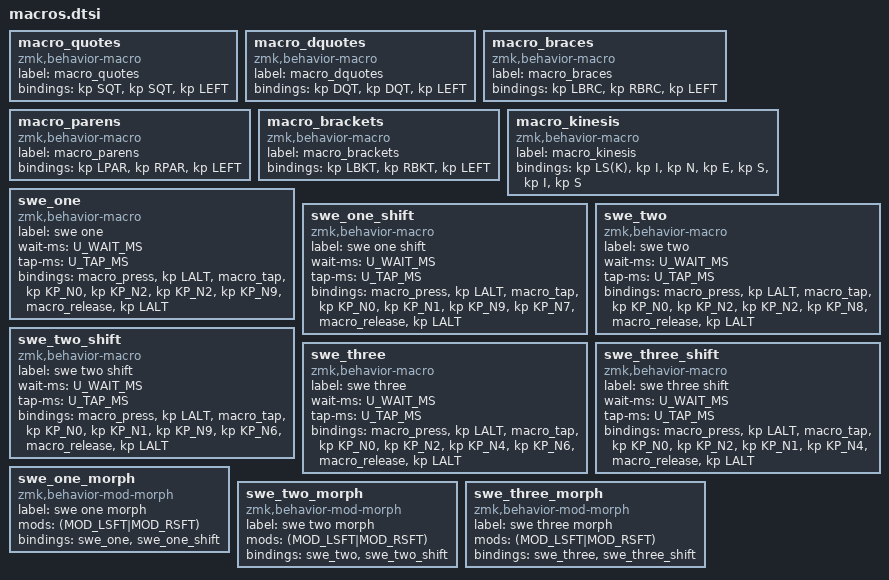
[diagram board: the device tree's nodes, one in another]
  macro_quotes: macro_quotes {
    compatible = "zmk,behavior-macro";
    label = "macro_quotes";
    #binding-cells = <0>;
    bindings = <&kp SQT>, <&kp SQT>, <&kp LEFT>;
  };
  macro_dquotes: macro_dquotes {
    compatible = "zmk,behavior-macro";
    label = "macro_dquotes";
    #binding-cells = <0>;
    bindings = <&kp DQT>, <&kp DQT>, <&kp LEFT>;
  };
  macro_braces: macro_braces {
    compatible = "zmk,behavior-macro";
    label = "macro_braces";
    #binding-cells = <0>;
    bindings = <&kp LBRC>, <&kp RBRC>, <&kp LEFT>;
  };
  macro_parens: macro_parens {
    compatible = "zmk,behavior-macro";
    label = "macro_parens";
    #binding-cells = <0>;
    bindings = <&kp LPAR>, <&kp RPAR>, <&kp LEFT>;
  };
  macro_brackets: macro_brackets {
    compatible = "zmk,behavior-macro";
    label = "macro_brackets";
    #binding-cells = <0>;
    bindings = <&kp LBKT>, <&kp RBKT>, <&kp LEFT>;
  };
  macro_kinesis: macro_kinesis {
    compatible = "zmk,behavior-macro";
    label = "macro_kinesis";
    #binding-cells = <0>;
    bindings = <&kp LS(K)>, <&kp I>, <&kp N>, <&kp E>, <&kp S>, <&kp I>, <&kp S>;
  };

  swe_one: swe_one {
      compatible = "zmk,behavior-macro";
      label = "swe one";
      #binding-cells = <0>;
      wait-ms = <U_WAIT_MS>;
      tap-ms = <U_TAP_MS>;
      bindings
        = <&macro_press   &kp LALT>
        , <&macro_tap     &kp KP_N0 &kp KP_N2 &kp KP_N2 &kp KP_N9>
        , <&macro_release &kp LALT>;
  };
  swe_one_shift: swe_one_shift {
      compatible = "zmk,behavior-macro";
      label = "swe one shift";
      #binding-cells = <0>;
      wait-ms = <U_WAIT_MS>;
      tap-ms = <U_TAP_MS>;
      bindings
        = <&macro_press   &kp LALT>
        , <&macro_tap     &kp KP_N0 &kp KP_N1 &kp KP_N9 &kp KP_N7>
        , <&macro_release &kp LALT>;
  };
  swe_two: swe_two {
      compatible = "zmk,behavior-macro";
      label = "swe two";
      #binding-cells = <0>;
      wait-ms = <U_WAIT_MS>;
      tap-ms = <U_TAP_MS>;
      bindings
        = <&macro_press   &kp LALT>
        , <&macro_tap     &kp KP_N0 &kp KP_N2 &kp KP_N2 &kp KP_N8>
        , <&macro_release &kp LALT>;
  };
  swe_two_shift: swe_two_shift {
      compatible = "zmk,behavior-macro";
      label = "swe two shift";
      #binding-cells = <0>;
      wait-ms = <U_WAIT_MS>;
      tap-ms = <U_TAP_MS>;
      bindings
        = <&macro_press   &kp LALT>
        , <&macro_tap     &kp KP_N0 &kp KP_N1 &kp KP_N9 &kp KP_N6>
        , <&macro_release &kp LALT>;
  };
  swe_three: swe_three {
      compatible = "zmk,behavior-macro";
      label = "swe three";
      #binding-cells = <0>;
      wait-ms = <U_WAIT_MS>;
      tap-ms = <U_TAP_MS>;
      bindings
        = <&macro_press   &kp LALT>
        , <&macro_tap     &kp KP_N0 &kp KP_N2 &kp KP_N4 &kp KP_N6>
        , <&macro_release &kp LALT>;
  };
  swe_three_shift: swe_three_shift {
      compatible = "zmk,behavior-macro";
      label = "swe three shift";
      #binding-cells = <0>;
      wait-ms = <U_WAIT_MS>;
      tap-ms = <U_TAP_MS>;
      bindings
        = <&macro_press   &kp LALT>
        , <&macro_tap     &kp KP_N0 &kp KP_N2 &kp KP_N1 &kp KP_N4>
        , <&macro_release &kp LALT>;
  };
  swe_one_morph: swe_one_morph {
      compatible = "zmk,behavior-mod-morph";
      label = "swe one morph";
      #binding-cells = <0>;
      mods = <(MOD_LSFT|MOD_RSFT)>;
      bindings = <&swe_one>, <&swe_one_shift>;
  };
  swe_two_morph: swe_two_morph {
      compatible = "zmk,behavior-mod-morph";
      label = "swe two morph";
      #binding-cells = <0>;
      mods = <(MOD_LSFT|MOD_RSFT)>;
      bindings = <&swe_two>, <&swe_two_shift>;
  };
  swe_three_morph: swe_three_morph {
      compatible = "zmk,behavior-mod-morph";
      label = "swe three morph";
      #binding-cells = <0>;
      mods = <(MOD_LSFT|MOD_RSFT)>;
      bindings = <&swe_three>, <&swe_three_shift>;
  };
